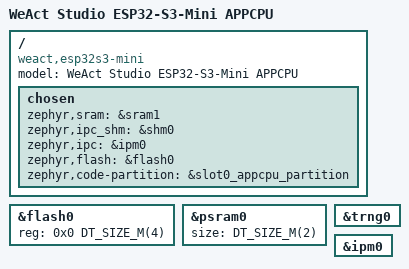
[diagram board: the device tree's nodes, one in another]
/*
 * Copyright (c) 2025 Siratul Islam <sirat4757@gmail.com>
 *
 * SPDX-License-Identifier: Apache-2.0
 */
/dts-v1/;

#include <espressif/esp32s3/esp32s3.dtsi>
#include <espressif/partitions_0x0_amp_4M.dtsi>
#include "weact_esp32s3_mini-pinctrl.dtsi"

/ {
	model = "WeAct Studio ESP32-S3-Mini APPCPU";
	compatible = "weact,esp32s3-mini";

	chosen {
		zephyr,sram = &sram1;
		zephyr,ipc_shm = &shm0;
		zephyr,ipc = &ipm0;
		zephyr,flash = &flash0;
		zephyr,code-partition = &slot0_appcpu_partition;
	};
};

&flash0 {
	reg = <0x0 DT_SIZE_M(4)>;
	ranges = <0x0 0x0 DT_SIZE_M(4)>;
};

&psram0 {
	size = <DT_SIZE_M(2)>;
};

&trng0 {
	status = "okay";
};

&ipm0 {
	status = "okay";
};
